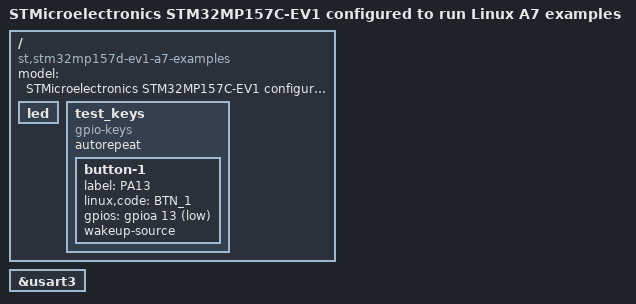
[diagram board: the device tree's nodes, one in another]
// SPDX-License-Identifier: (GPL-2.0-only OR BSD-3-Clause)
/*
 * Copyright (C) STMicroelectronics 2026 - All Rights Reserved
 * Author: Amelie Delaunay <amelie.delaunay@foss.st.com> for STMicroelectronics.
 */

/dts-v1/;

#include "stm32mp157d-ev1.dts"
#include <dt-bindings/input/input.h>

/ {
	model = "STMicroelectronics STM32MP157C-EV1 configured to run Linux A7 examples";
	compatible = "st,stm32mp157d-ev1-a7-examples", "st,stm32mp157d-ev1", "st,stm32mp157d-ed1", "st,stm32mp157";

	led {
		/* free GPIOA13 used by red led to use it as button-1 gpio */
		/delete-node/ led-red;
	};

	test_keys {
		compatible = "gpio-keys";
		autorepeat;
		status = "okay";

		button-1 {
				label = "PA13";
				linux,code = <BTN_1>;
				gpios = <&gpioa 13 (GPIO_ACTIVE_LOW | GPIO_PULL_UP)>;
				status = "okay";
				wakeup-source;
		};
	};
};

&usart3 {
	status = "okay";
};
